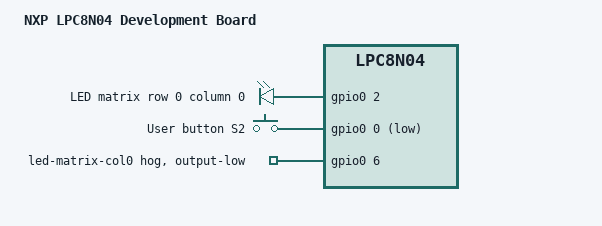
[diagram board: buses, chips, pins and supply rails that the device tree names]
/*
 * SPDX-FileCopyrightText: Copyright The Zephyr Project Contributors
 * SPDX-License-Identifier: Apache-2.0
 */

/dts-v1/;

#include <nxp/lpc/lpc8n04/nxp_lpc8n04.dtsi>
#include <zephyr/dt-bindings/gpio/gpio.h>
#include <zephyr/dt-bindings/input/input-event-codes.h>

/ {
	model = "NXP LPC8N04 Development Board";
	compatible = "nxp,lpc8n04-devboard";

	chosen {
		zephyr,sram = &sram0;
		zephyr,flash = &flash0;
	};

	aliases {
		led0 = &led_matrix_r0c0;
		sw0 = &user_button;
	};

	/* Rows drive the LED anodes; the hog below holds column 0 low. */
	leds {
		compatible = "gpio-leds";

		led_matrix_r0c0: led_0 {
			gpios = <&gpio0 2 GPIO_ACTIVE_HIGH>;
			label = "LED matrix row 0 column 0";
		};
	};

	gpio_keys {
		compatible = "gpio-keys";

		user_button: button_0 {
			gpios = <&gpio0 0 (GPIO_PULL_UP | GPIO_ACTIVE_LOW)>;
			label = "User button S2";
			zephyr,code = <INPUT_KEY_0>;
		};
	};
};

&gpio0 {
	status = "okay";

	led-col0-hog {
		gpio-hog;
		gpios = <6 GPIO_ACTIVE_HIGH>;
		output-low;
		line-name = "led-matrix-col0";
	};
};
